# f2837xs_gpio_ctrl_regs register map
Vendor: Texas Instruments
Peripheral module from a debugger description file (folder C2000).
Address unit: 16 bits
Registers are 32-bit, read-write, no defined reset value unless marked. A register's access mark holds for its fields unless they carry their own. Offsets are as the file gives them; lines under a group give offsets from that group; [hi:lo] are bit positions; {n}, {i} and the like mark numbered series; 'fields as' and 'values as' point back to an identical list; <NAME> marks a mode.

## GPIO_CTRL_REGS — GPIO CTRL Registers
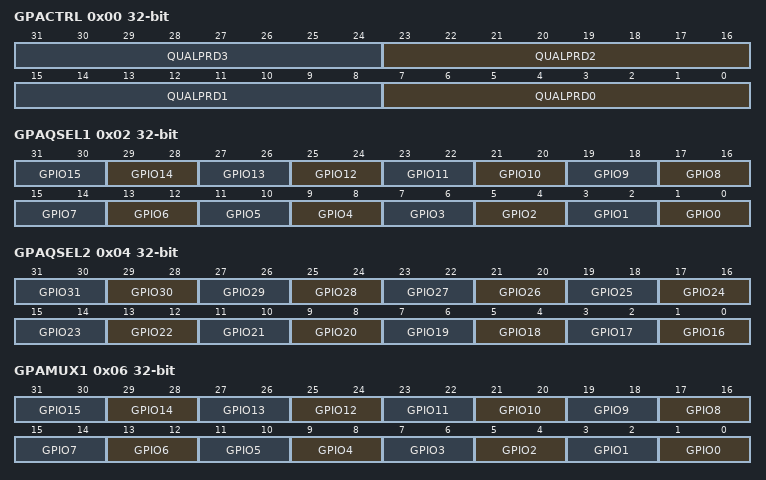
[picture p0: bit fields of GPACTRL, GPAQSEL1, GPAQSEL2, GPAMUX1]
0x00 GPACTRL — GPIO A Qualification Sampling Period Control (GPIO0 to 31)
  [8n+7:8n] QUALPRD{n} (n=0..3) — Qualification sampling period for GPIO{8n} to GPIO{8n+7}
0x02 GPAQSEL1 — GPIO A Qualifier Select 1 Register (GPIO0 to 15)
  [2n+1:2n] GPIO{n} (n=0..15) — Select input qualification type for GPIO{n}
0x04 GPAQSEL2 — GPIO A Qualifier Select 2 Register (GPIO16 to 31)
  [2n-31:2n-32] GPIO{n} (n=16..31) — Select input qualification type for GPIO{n}
0x06 GPAMUX1 — GPIO A Mux 1 Register (GPIO0 to 15)
  [2n+1:2n] GPIO{n} (n=0..15) — Defines pin-muxing selection for GPIO{n}
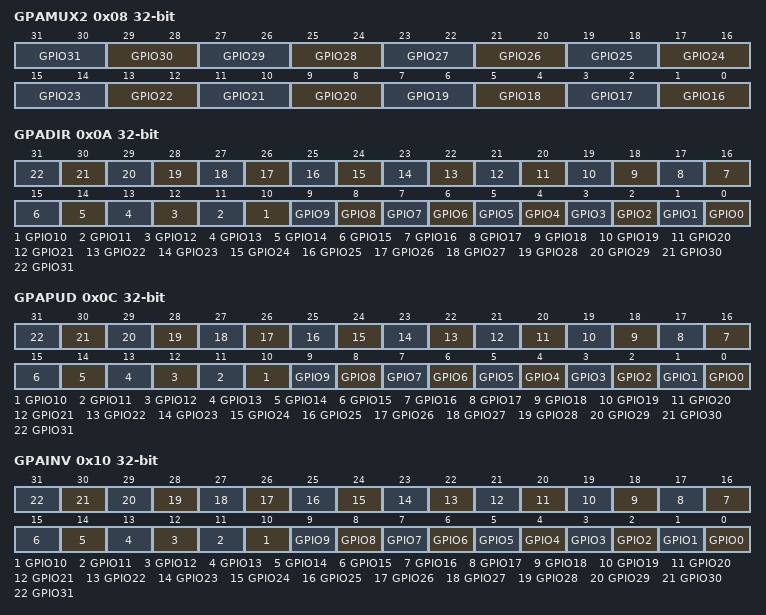
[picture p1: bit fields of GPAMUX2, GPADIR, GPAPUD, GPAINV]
0x08 GPAMUX2 — GPIO A Mux 2 Register (GPIO16 to 31)
  [2n-31:2n-32] GPIO{n} (n=16..31) — Defines pin-muxing selection for GPIO{n}
0x0A GPADIR — GPIO A Direction Register (GPIO0 to 31)
  [n] GPIO{n} (n=0..31) — Defines direction for this pin in GPIO mode
0x0C GPAPUD — GPIO A Pull Up Disable Register (GPIO0 to 31)
  [n] GPIO{n} (n=0..31) — Pull-Up Disable control for this pin
0x10 GPAINV — GPIO A Input Polarity Invert Registers (GPIO0 to 31)
  [n] GPIO{n} (n=0..31) — Input inversion control for this pin
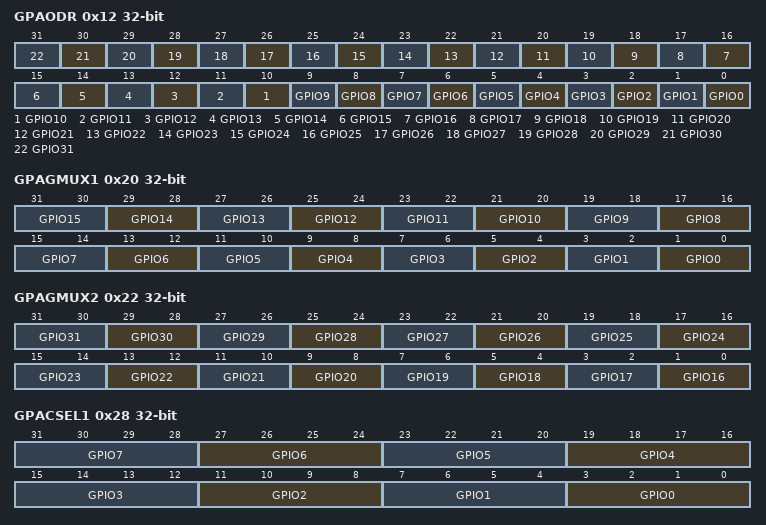
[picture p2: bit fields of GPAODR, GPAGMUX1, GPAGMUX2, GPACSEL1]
0x12 GPAODR — GPIO A Open Drain Output Register (GPIO0 to GPIO31)
  [n] GPIO{n} (n=0..31) — Outpout Open-Drain control for this pin
0x20 GPAGMUX1 — GPIO A Peripheral Group Mux (GPIO0 to 15)
  fields as GPAMUX1
0x22 GPAGMUX2 — GPIO A Peripheral Group Mux (GPIO16 to 31)
  fields as GPAMUX2
0x28 GPACSEL1 — GPIO A Core Select Register (GPIO0 to 7)
  [4n+3:4n] GPIO{n} (n=0..7) — GPIO{n} Master CPU Select
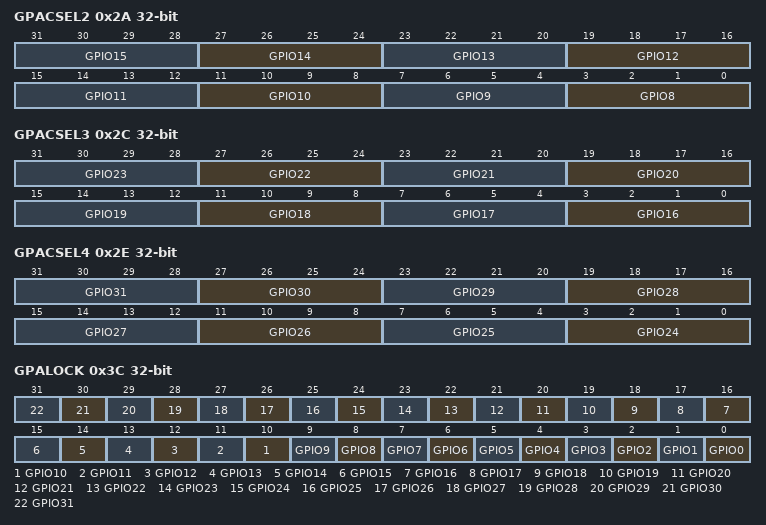
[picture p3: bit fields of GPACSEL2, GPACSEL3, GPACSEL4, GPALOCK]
0x2A GPACSEL2 — GPIO A Core Select Register (GPIO8 to 15)
  [4n-29:4n-32] GPIO{n} (n=8..15) — GPIO{n} Master CPU Select
0x2C GPACSEL3 — GPIO A Core Select Register (GPIO16 to 23)
  [4n-61:4n-64] GPIO{n} (n=16..23) — GPIO{n} Master CPU Select
0x2E GPACSEL4 — GPIO A Core Select Register (GPIO24 to 31)
  [4n-93:4n-96] GPIO{n} (n=24..31) — GPIO{n} Master CPU Select
0x3C GPALOCK — GPIO A Lock Configuration Register (GPIO0 to 31)
  [n] GPIO{n} (n=0..31) — Configuration Lock bit for this pin
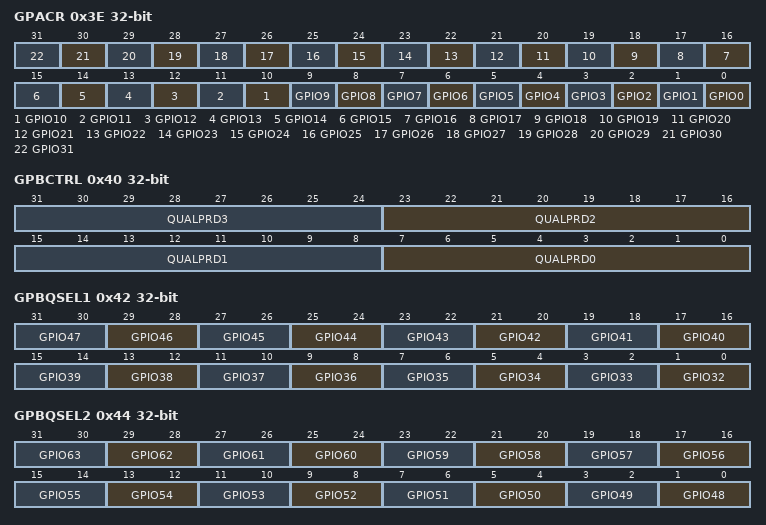
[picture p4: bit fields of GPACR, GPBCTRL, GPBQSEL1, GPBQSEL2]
0x3E GPACR access not given — GPIO A Lock Commit Register (GPIO0 to 31)
  [n] GPIO{n} (n=0..31) — Configuration lock commit bit for this pin (access R/WOnce)
0x40 GPBCTRL — GPIO B Qualification Sampling Period Control (GPIO32 to 63)
  [8n+7:8n] QUALPRD{n} (n=0..3) — Qualification sampling period for GPIO{8n+32} to GPIO{8n+39}
0x42 GPBQSEL1 — GPIO B Qualifier Select 1 Register (GPIO32 to 47)
  [2n-63:2n-64] GPIO{n} (n=32..47) — Select input qualification type for GPIO{n}
0x44 GPBQSEL2 — GPIO B Qualifier Select 2 Register (GPIO48 to 63)
  [2n-95:2n-96] GPIO{n} (n=48..63) — Select input qualification type for GPIO{n}
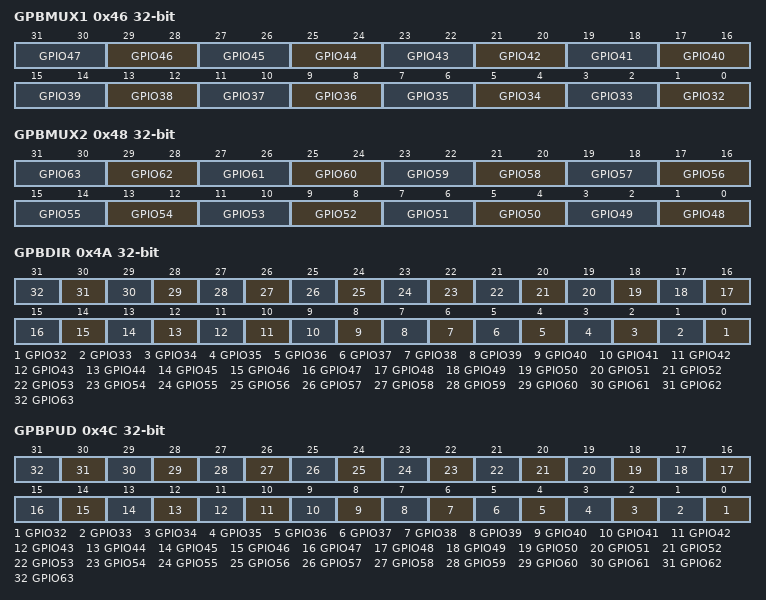
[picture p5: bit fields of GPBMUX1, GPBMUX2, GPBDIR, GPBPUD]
0x46 GPBMUX1 — GPIO B Mux 1 Register (GPIO32 to 47)
  [2n-63:2n-64] GPIO{n} (n=32..47) — Defines pin-muxing selection for GPIO{n}
0x48 GPBMUX2 — GPIO B Mux 2 Register (GPIO48 to 63)
  [2n-95:2n-96] GPIO{n} (n=48..63) — Defines pin-muxing selection for GPIO{n}
0x4A GPBDIR — GPIO B Direction Register (GPIO32 to 63)
  [n-32] GPIO{n} (n=32..63) — Defines direction for this pin in GPIO mode
0x4C GPBPUD — GPIO B Pull Up Disable Register (GPIO32 to 63)
  [n-32] GPIO{n} (n=32..63) — Pull-Up Disable control for this pin
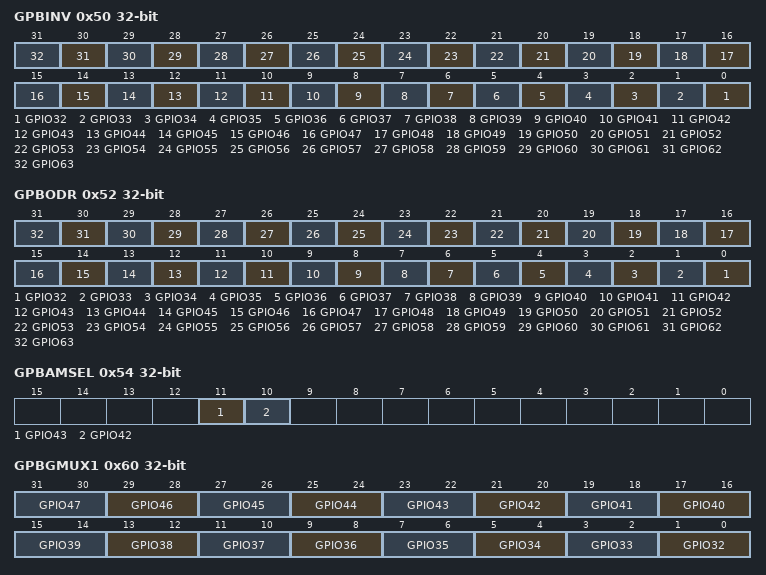
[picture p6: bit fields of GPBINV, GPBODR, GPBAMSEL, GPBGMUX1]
0x50 GPBINV — GPIO B Input Polarity Invert Registers (GPIO32 to 63)
  [n-32] GPIO{n} (n=32..63) — Input inversion control for this pin
0x52 GPBODR — GPIO B Open Drain Output Register (GPIO32 to GPIO63)
  [n-32] GPIO{n} (n=32..63) — Outpout Open-Drain control for this pin
0x54 GPBAMSEL — GPIO B Analog Mode Select register (GPIO32 to GPIO63)
  [11] GPIO43 — Analog Mode select for this pin
  [10] GPIO42 — Analog Mode select for this pin
0x60 GPBGMUX1 — GPIO B Peripheral Group Mux (GPIO32 to 47)
  fields as GPBMUX1
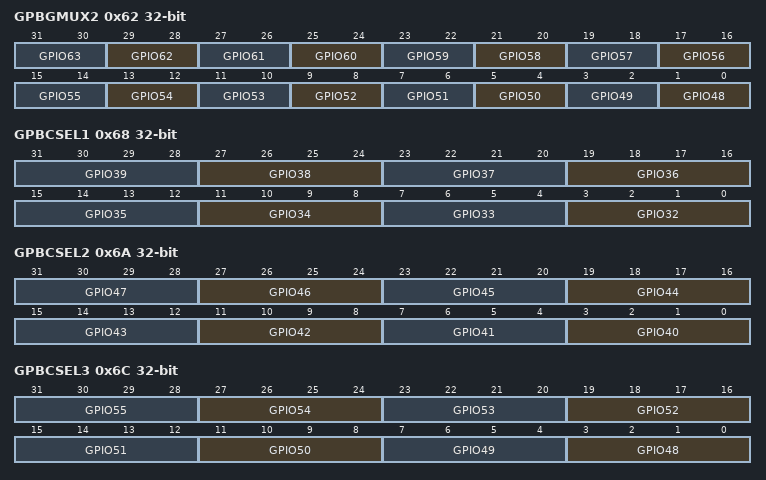
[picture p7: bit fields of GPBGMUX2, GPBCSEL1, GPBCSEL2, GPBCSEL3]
0x62 GPBGMUX2 — GPIO B Peripheral Group Mux (GPIO48 to 63)
  fields as GPBMUX2
0x68 GPBCSEL1 — GPIO B Core Select Register (GPIO32 to 39)
  [4n-125:4n-128] GPIO{n} (n=32..39) — GPIO{n} Master CPU Select
0x6A GPBCSEL2 — GPIO B Core Select Register (GPIO40 to 47)
  [4n-157:4n-160] GPIO{n} (n=40..47) — GPIO{n} Master CPU Select
0x6C GPBCSEL3 — GPIO B Core Select Register (GPIO48 to 55)
  [4n-189:4n-192] GPIO{n} (n=48..55) — GPIO{n} Master CPU Select
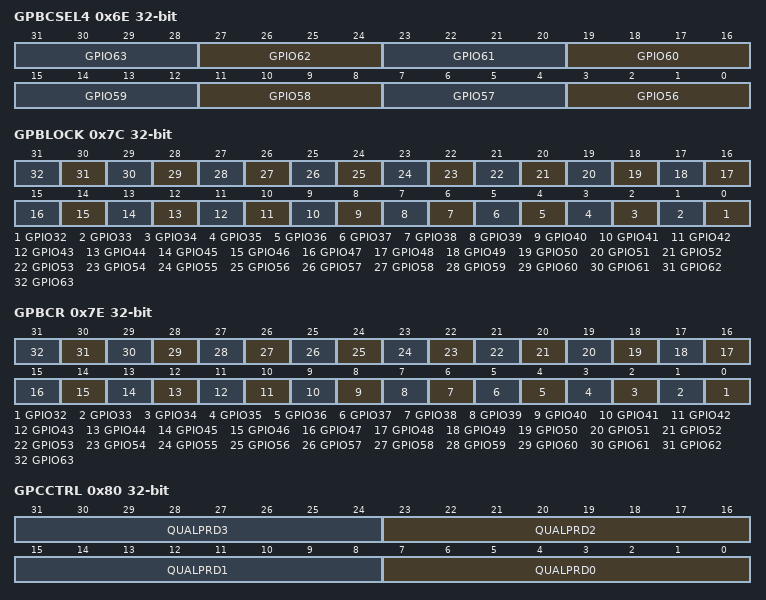
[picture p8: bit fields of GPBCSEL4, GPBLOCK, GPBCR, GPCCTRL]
0x6E GPBCSEL4 — GPIO B Core Select Register (GPIO56 to 63)
  [4n-221:4n-224] GPIO{n} (n=56..63) — GPIO{n} Master CPU Select
0x7C GPBLOCK — GPIO B Lock Configuration Register (GPIO32 to 63)
  [n-32] GPIO{n} (n=32..63) — Configuration Lock bit for this pin
0x7E GPBCR access not given — GPIO B Lock Commit Register (GPIO32 to 63)
  [n-32] GPIO{n} (n=32..63) — Configuration lock commit bit for this pin (access R/WOnce)
0x80 GPCCTRL — GPIO C Qualification Sampling Period Control (GPIO64 to 95)
  [8n+7:8n] QUALPRD{n} (n=0..3) — Qualification sampling period for GPIO{8n+64} to GPIO{8n+71}
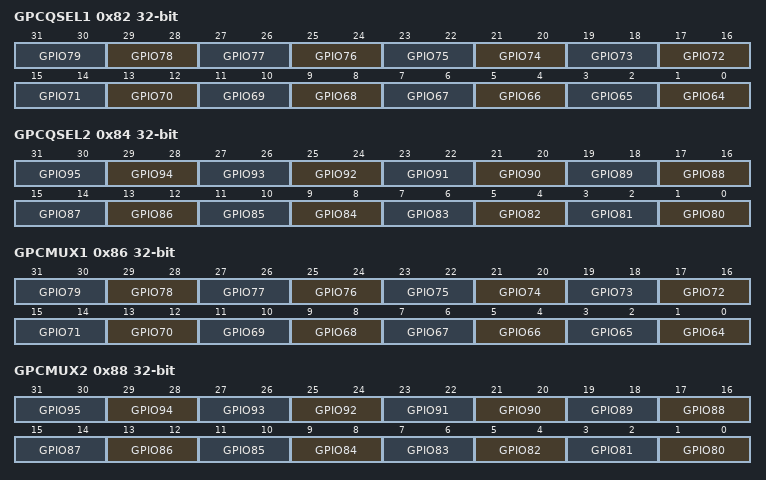
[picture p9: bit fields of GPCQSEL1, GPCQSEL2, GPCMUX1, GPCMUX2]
0x82 GPCQSEL1 — GPIO C Qualifier Select 1 Register (GPIO64 to 79)
  [2n-127:2n-128] GPIO{n} (n=64..79) — Select input qualification type for GPIO{n}
0x84 GPCQSEL2 — GPIO C Qualifier Select 2 Register (GPIO80 to 95)
  [2n-159:2n-160] GPIO{n} (n=80..95) — Select input qualification type for GPIO{n}
0x86 GPCMUX1 — GPIO C Mux 1 Register (GPIO64 to 79)
  [2n-127:2n-128] GPIO{n} (n=64..79) — Defines pin-muxing selection for GPIO{n}
0x88 GPCMUX2 — GPIO C Mux 2 Register (GPIO80 to 95)
  [2n-159:2n-160] GPIO{n} (n=80..95) — Defines pin-muxing selection for GPIO{n}
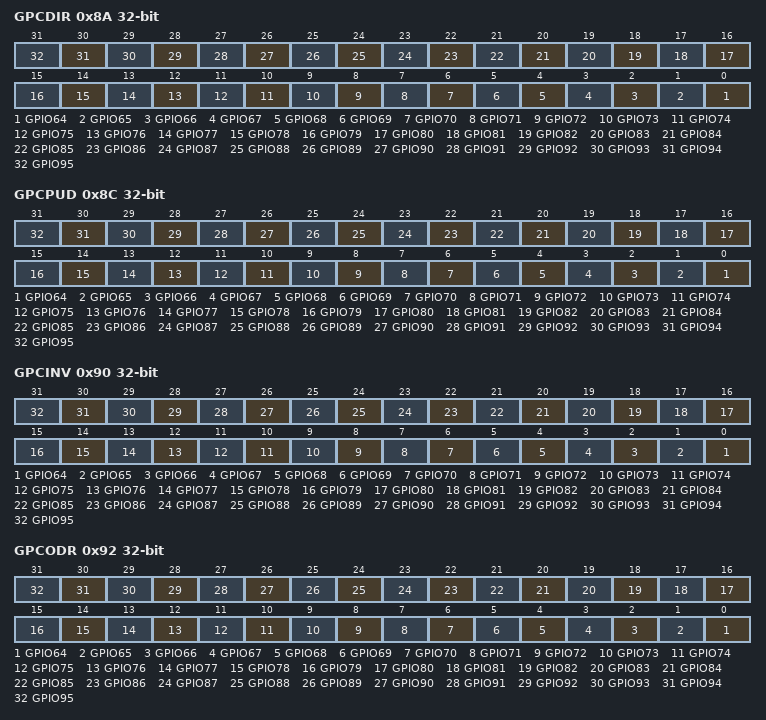
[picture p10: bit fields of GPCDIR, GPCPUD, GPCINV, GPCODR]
0x8A GPCDIR — GPIO C Direction Register (GPIO64 to 95)
  [n-64] GPIO{n} (n=64..95) — Defines direction for this pin in GPIO mode
0x8C GPCPUD — GPIO C Pull Up Disable Register (GPIO64 to 95)
  [n-64] GPIO{n} (n=64..95) — Pull-Up Disable control for this pin
0x90 GPCINV — GPIO C Input Polarity Invert Registers (GPIO64 to 95)
  [n-64] GPIO{n} (n=64..95) — Input inversion control for this pin
0x92 GPCODR — GPIO C Open Drain Output Register (GPIO64 to GPIO95)
  [n-64] GPIO{n} (n=64..95) — Outpout Open-Drain control for this pin
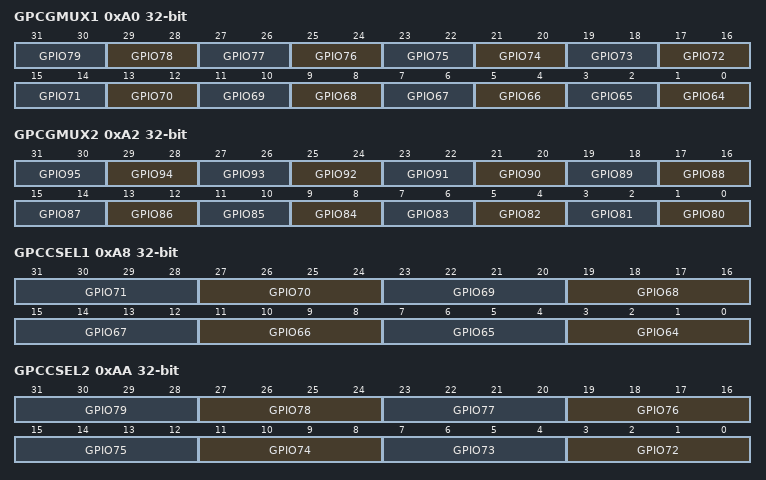
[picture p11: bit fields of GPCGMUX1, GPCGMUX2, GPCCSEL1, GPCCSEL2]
0xA0 GPCGMUX1 — GPIO C Peripheral Group Mux (GPIO64 to 79)
  fields as GPCMUX1
0xA2 GPCGMUX2 — GPIO C Peripheral Group Mux (GPIO80 to 95)
  fields as GPCMUX2
0xA8 GPCCSEL1 — GPIO C Core Select Register (GPIO64 to 71)
  [4n-253:4n-256] GPIO{n} (n=64..71) — GPIO{n} Master CPU Select
0xAA GPCCSEL2 — GPIO C Core Select Register (GPIO72 to 79)
  [4n-285:4n-288] GPIO{n} (n=72..79) — GPIO{n} Master CPU Select
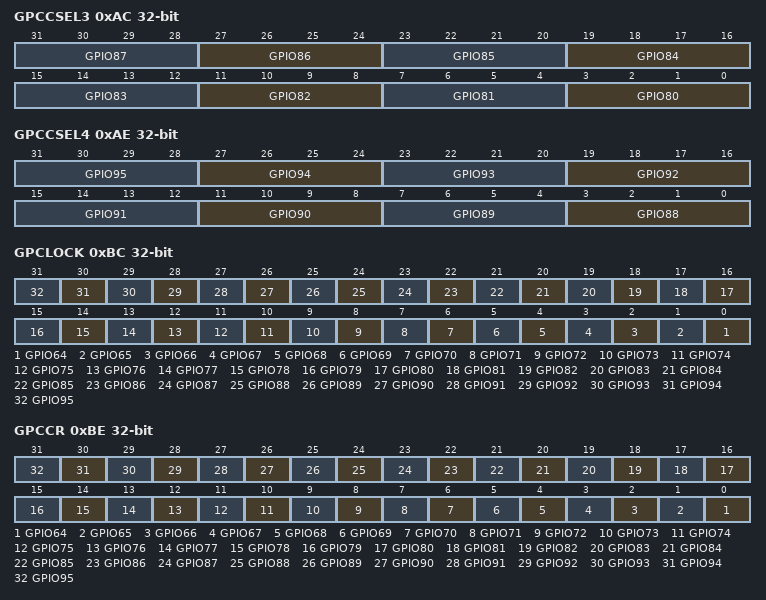
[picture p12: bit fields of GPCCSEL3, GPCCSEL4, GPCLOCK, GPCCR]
0xAC GPCCSEL3 — GPIO C Core Select Register (GPIO80 to 87)
  [4n-317:4n-320] GPIO{n} (n=80..87) — GPIO{n} Master CPU Select
0xAE GPCCSEL4 — GPIO C Core Select Register (GPIO88 to 95)
  [4n-349:4n-352] GPIO{n} (n=88..95) — GPIO{n} Master CPU Select
0xBC GPCLOCK — GPIO C Lock Configuration Register (GPIO64 to 95)
  [n-64] GPIO{n} (n=64..95) — Configuration Lock bit for this pin
0xBE GPCCR access not given — GPIO C Lock Commit Register (GPIO64 to 95)
  [n-64] GPIO{n} (n=64..95) — Configuration lock commit bit for this pin (access R/WOnce)
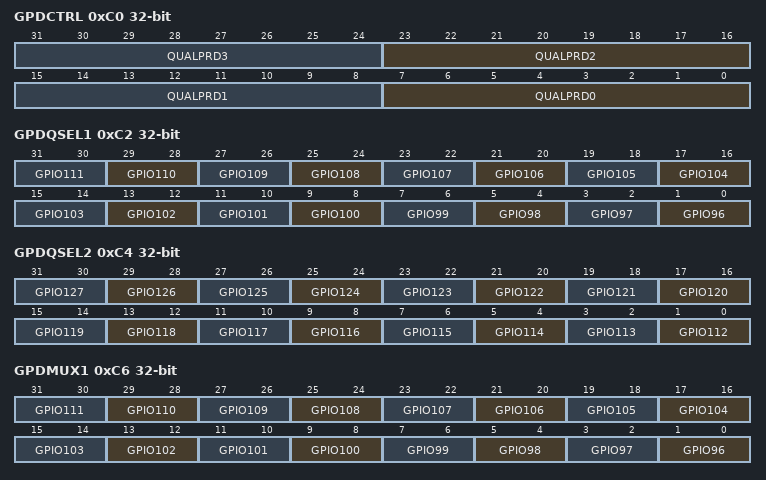
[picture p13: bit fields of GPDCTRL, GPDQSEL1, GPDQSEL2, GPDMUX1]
0xC0 GPDCTRL — GPIO D Qualification Sampling Period Control (GPIO96 to 127)
  [8n+7:8n] QUALPRD{n} (n=0..3) — Qualification sampling period for GPIO{8n+96} to GPIO{8n+103}
0xC2 GPDQSEL1 — GPIO D Qualifier Select 1 Register (GPIO96 to 111)
  [2n-191:2n-192] GPIO{n} (n=96..111) — Select input qualification type for GPIO{n}
0xC4 GPDQSEL2 — GPIO D Qualifier Select 2 Register (GPIO112 to 127)
  [2n-223:2n-224] GPIO{n} (n=112..127) — Select input qualification type for GPIO{n}
0xC6 GPDMUX1 — GPIO D Mux 1 Register (GPIO96 to 111)
  [2n-191:2n-192] GPIO{n} (n=96..111) — Defines pin-muxing selection for GPIO{n}
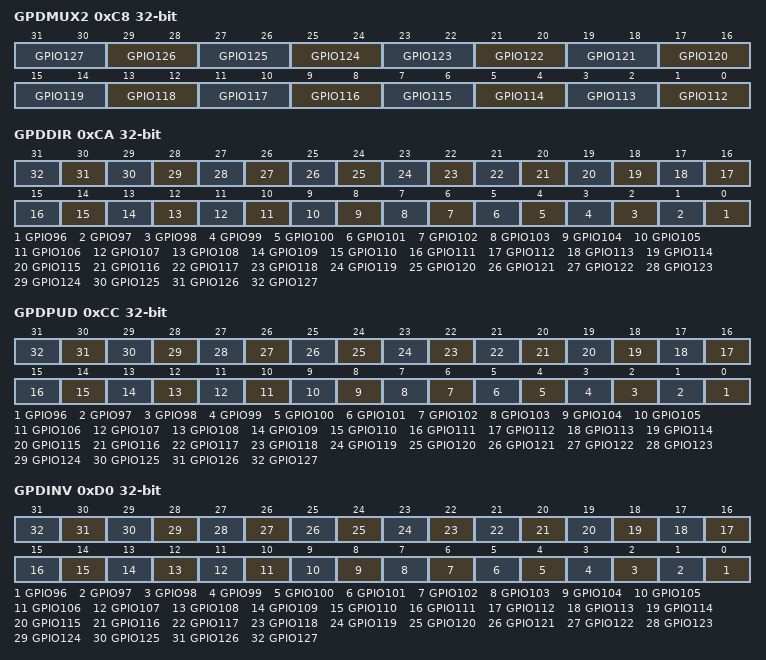
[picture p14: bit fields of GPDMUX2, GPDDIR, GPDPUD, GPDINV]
0xC8 GPDMUX2 — GPIO D Mux 2 Register (GPIO112 to 127)
  [2n-223:2n-224] GPIO{n} (n=112..127) — Defines pin-muxing selection for GPIO{n}
0xCA GPDDIR — GPIO D Direction Register (GPIO96 to 127)
  [n-96] GPIO{n} (n=96..127) — Defines direction for this pin in GPIO mode
0xCC GPDPUD — GPIO D Pull Up Disable Register (GPIO96 to 127)
  [n-96] GPIO{n} (n=96..127) — Pull-Up Disable control for this pin
0xD0 GPDINV — GPIO D Input Polarity Invert Registers (GPIO96 to 127)
  [n-96] GPIO{n} (n=96..127) — Input inversion control for this pin
0xD2 GPDODR — GPIO D Open Drain Output Register (GPIO96 to GPIO127)
  [n-96] GPIO{n} (n=96..127) — Outpout Open-Drain control for this pin
0xE0 GPDGMUX1 — GPIO D Peripheral Group Mux (GPIO96 to 111)
  fields as GPDMUX1
0xE2 GPDGMUX2 — GPIO D Peripheral Group Mux (GPIO112 to 127)
  fields as GPDMUX2
0xE8 GPDCSEL1 — GPIO D Core Select Register (GPIO96 to 103)
  [4n-381:4n-384] GPIO{n} (n=96..103) — GPIO{n} Master CPU Select
0xEA GPDCSEL2 — GPIO D Core Select Register (GPIO104 to 111)
  [4n-413:4n-416] GPIO{n} (n=104..111) — GPIO{n} Master CPU Select
0xEC GPDCSEL3 — GPIO D Core Select Register (GPIO112 to 119)
  [4n-445:4n-448] GPIO{n} (n=112..119) — GPIO{n} Master CPU Select
0xEE GPDCSEL4 — GPIO D Core Select Register (GPIO120 to 127)
  [4n-477:4n-480] GPIO{n} (n=120..127) — GPIO{n} Master CPU Select
0xFC GPDLOCK — GPIO D Lock Configuration Register (GPIO96 to 127)
  [n-96] GPIO{n} (n=96..127) — Configuration Lock bit for this pin
0xFE GPDCR access not given — GPIO D Lock Commit Register (GPIO96 to 127)
  [n-96] GPIO{n} (n=96..127) — Configuration lock commit bit for this pin (access R/WOnce)
0x100 GPECTRL — GPIO E Qualification Sampling Period Control (GPIO128 to 159)
  [8n+7:8n] QUALPRD{n} (n=0..3) — Qualification sampling period for GPIO{8n+128} to GPIO{8n+135}
0x102 GPEQSEL1 — GPIO E Qualifier Select 1 Register (GPIO128 to 143)
  [2n-255:2n-256] GPIO{n} (n=128..143) — Select input qualification type for GPIO{n}
0x104 GPEQSEL2 — GPIO E Qualifier Select 2 Register (GPIO144 to 159)
  [2n-287:2n-288] GPIO{n} (n=144..159) — Select input qualification type for GPIO{n}
0x106 GPEMUX1 — GPIO E Mux 1 Register (GPIO128 to 143)
  [2n-255:2n-256] GPIO{n} (n=128..143) — Defines pin-muxing selection for GPIO{n}
0x108 GPEMUX2 — GPIO E Mux 2 Register (GPIO144 to 159)
  [2n-287:2n-288] GPIO{n} (n=144..159) — Defines pin-muxing selection for GPIO{n}
0x10A GPEDIR — GPIO E Direction Register (GPIO128 to 159)
  [n-128] GPIO{n} (n=128..159) — Defines direction for this pin in GPIO mode
0x10C GPEPUD — GPIO E Pull Up Disable Register (GPIO128 to 159)
  [n-128] GPIO{n} (n=128..159) — Pull-Up Disable control for this pin
0x110 GPEINV — GPIO E Input Polarity Invert Registers (GPIO128 to 159)
  [n-128] GPIO{n} (n=128..159) — Input inversion control for this pin
0x112 GPEODR — GPIO E Open Drain Output Register (GPIO128 to GPIO159)
  [n-128] GPIO{n} (n=128..159) — Outpout Open-Drain control for this pin
0x120 GPEGMUX1 — GPIO E Peripheral Group Mux (GPIO128 to 143)
  fields as GPEMUX1
0x122 GPEGMUX2 — GPIO E Peripheral Group Mux (GPIO144 to 159)
  fields as GPEMUX2
0x128 GPECSEL1 — GPIO E Core Select Register (GPIO128 to 135)
  [4n-509:4n-512] GPIO{n} (n=128..135) — GPIO{n} Master CPU Select
0x12A GPECSEL2 — GPIO E Core Select Register (GPIO136 to 143)
  [4n-541:4n-544] GPIO{n} (n=136..143) — GPIO{n} Master CPU Select
0x12C GPECSEL3 — GPIO E Core Select Register (GPIO144 to 151)
  [4n-573:4n-576] GPIO{n} (n=144..151) — GPIO{n} Master CPU Select
0x12E GPECSEL4 — GPIO E Core Select Register (GPIO152 to 159)
  [4n-605:4n-608] GPIO{n} (n=152..159) — GPIO{n} Master CPU Select
0x13C GPELOCK — GPIO E Lock Configuration Register (GPIO128 to 159)
  [n-128] GPIO{n} (n=128..159) — Configuration Lock bit for this pin
0x13E GPECR access not given — GPIO E Lock Commit Register (GPIO128 to 159)
  [n-128] GPIO{n} (n=128..159) — Configuration lock commit bit for this pin (access R/WOnce)
0x140 GPFCTRL — GPIO F Qualification Sampling Period Control (GPIO160 to 168)
  [15:8] QUALPRD1 — Qualification sampling period for GPIO168
  [7:0] QUALPRD0 — Qualification sampling period for GPIO160 to GPIO167
0x142 GPFQSEL1 — GPIO F Qualifier Select 1 Register (GPIO160 to 168)
  [2n-319:2n-320] GPIO{n} (n=160..168) — Select input qualification type for GPIO{n}
0x146 GPFMUX1 — GPIO F Mux 1 Register (GPIO160 to 168)
  [2n-319:2n-320] GPIO{n} (n=160..168) — Defines pin-muxing selection for GPIO{n}
0x14A GPFDIR — GPIO F Direction Register (GPIO160 to 168)
  [n-160] GPIO{n} (n=160..168) — Defines direction for this pin in GPIO mode
0x14C GPFPUD — GPIO F Pull Up Disable Register (GPIO160 to 168)
  [n-160] GPIO{n} (n=160..168) — Pull-Up Disable control for this pin
0x150 GPFINV — GPIO F Input Polarity Invert Registers (GPIO160 to 168)
  [n-160] GPIO{n} (n=160..168) — Input inversion control for this pin
0x152 GPFODR — GPIO F Open Drain Output Register (GPIO160 to GPIO168)
  [n-160] GPIO{n} (n=160..168) — Outpout Open-Drain control for this pin
0x160 GPFGMUX1 — GPIO F Peripheral Group Mux (GPIO160 to 168)
  fields as GPFMUX1
0x168 GPFCSEL1 — GPIO F Core Select Register (GPIO160 to 167)
  [4n-637:4n-640] GPIO{n} (n=160..167) — GPIO{n} Master CPU Select
0x16A GPFCSEL2 — GPIO F Core Select Register (GPIO168)
  [3:0] GPIO168 — GPIO168 Master CPU Select
0x17C GPFLOCK — GPIO F Lock Configuration Register (GPIO160 to 168)
  [n-160] GPIO{n} (n=160..168) — Configuration Lock bit for this pin
0x17E GPFCR access not given — GPIO F Lock Commit Register (GPIO160 to 168)
  [n-160] GPIO{n} (n=160..168) — Configuration lock commit bit for this pin (access R/WOnce)
